# D1H register map
Vendor: Allwinner; File version: 1.0
Registers are 32-bit, read-write, reset 0x0 unless marked. A register's access mark holds for its fields unless they carry their own. Offsets are from the block's base; [hi:lo] are bit positions; {n}, {i} and the like mark numbered series.

## SPI0 — Serial Peripheral Interface
Base 0x04025000
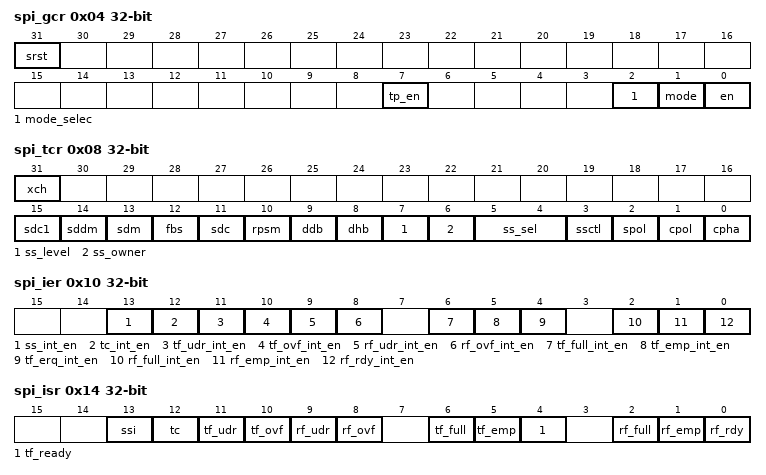
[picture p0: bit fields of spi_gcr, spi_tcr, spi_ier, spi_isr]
0x04 spi_gcr — SPI Global Control Register
  [31] srst — Soft reset
  [7] tp_en — Transmit Pause Enable
    0=NORMAL (normal operation, ignore RXFIFO status); 1=STOP_WHEN_FULL (Stop transmit data when RXFIFO full)
  [2] mode_selec — Sample timing Mode Select
    0=OLD_MODE (Old mode of Sample Timing); 1=NEW_MODE (New mode of Sample Timing)
  [1] mode — SPI Function Mode Select
    0=SLAVE; 1=MASTER
  [0] en — SPI Module Enable Control
    0=DISABLE; 1=ENABLE
0x08 spi_tcr — SPI Transfer Control Register
  [31] xch — Exchange Burst
    0=IDLE; 1=INITIATE_EXCHANGE
  [15] sdc1 — Master Sample Data Control register1
    0=NORMAL (normal operation, do not delay the internal read sample point); 1=DELAY (delay the internal read sample point)
  [14] sddm — Sending Data Delay Mode
    0=NORMAL (normal sending); 1=DELAY (delay sending)
  [13] sdm — Master Sample Data Mode
    0=DELAY (delay sample mode); 1=NORMAL (normal sample mode)
  [12] fbs — First Transmit Bit Select
    0=MSB (MSB first); 1=LSB (LSB first)
  [11] sdc — Master Sample Data Control
    0=NORMAL (Normal operation, do not delay the internal read sample point); 1=DELAY (Delay the internal read sample point)
  [10] rpsm — Rapids Mode Select
    0=NORMAL (Normal write mode); 1=RAPID (Rapid write mode)
  [9] ddb — Dummy Burst Type
    0=ZERO (The bit value of dummy SPI burst is zero); 1=ONE (The bit value of dummy SPI burst is one)
  [8] dhb — Discard Hash Burst
    0=RECEIVE (Receiving all SPI bursts in the BC period); 1=DISCARD (Discard unused SPI bursts)
  [7] ss_level
    0=LOW; 1=HIGH
  [6] ss_owner
    0=SPI_CONTROLLER; 1=SOFTWARE
  [5:4] ss_sel
    {v}=SS{v} (v=0..3)
  [3] ssctl
    0=ASSERT (SPI_SSx remains asserted between SPI bursts); 1=NEGATE (Negate SPI_SSx between SPI bursts)
  [2] spol — SPI Chip Select Signal Polarity Control
    0=HIGH (Active high polarity); 1=LOW (Active low polarity)
  [1] cpol — SPI Clock Polarity Control
    0=HIGH (Active high polarity); 1=LOW (Active low polarity)
  [0] cpha — SPI Clock/Data Phase Control
    0=P0 (Phase 0 (Leading edge for sample data)); 1=P1 (Phase 1 (Leading edge for setup data))
0x10 spi_ier — SPI Interrupt Control Register
  [all] fields
    0=DISABLE; 1=ENABLE
  [13] ss_int_en — SSI Interrupt Enable
  [12] tc_int_en — Transfer Completed Interrupt Enable
  [11] tf_udr_int_en — TXFIFO Underrun Interrupt Enable
  [10] tf_ovf_int_en — TXFIFO Overflow Interrupt Enable
  [9] rf_udr_int_en — RXFIFO Underrun Interrupt Enable
  [8] rf_ovf_int_en — RXFIFO Overflow Interrupt Enable
  [6] tf_full_int_en — TXFIFO Full Interrupt Enable
  [5] tf_emp_int_en — TXFIFO Empty Interrupt Enable
  [4] tf_erq_int_en — TXFIFO Empty Request Interrupt Enable
  [2] rf_full_int_en — RXFIFO Full Interrupt Enable
  [1] rf_emp_int_en — RXFIFO Empty Interrupt Enable
  [0] rf_rdy_int_en — RXFIFO Ready Request Interrupt Enable
0x14 spi_isr — SPI Interrupt Status Register
  [13] ssi — SS Invalid Enable
  [12] tc — Transfer Completed
    0=BUSY; 1=TRANSFER_COMPLETED
  [11] tf_udr — TXFIFO Underrun
    0=NOT_UNDERRUN; 1=UNDERRUN
  [10] tf_ovf — TXFIFO Overflow
    0=NOT_OVERFLOW; 1=OVERFLOW
  [9] rf_udr — RXFIFO Underrun
    0=NOT_UNDERRUN; 1=UNDERRUN
  [8] rf_ovf — RXFIFO Overflow
    0=NOT_OVERFLOW; 1=OVERFLOW
  [6] tf_full — TXFIFO Full
    0=NOT_FULL; 1=FULL
  [5] tf_emp — TXFIFO Empty
    0=NOT_EMPTY; 1=EMPTY
  [4] tf_ready — TXFIFO Ready
  [2] rf_full — RXFIFO Full
    0=NOT_FULL; 1=FULL
  [1] rf_emp — RXFIFO Empty
    0=NOT_EMPTY; 1=EMPTY
  [0] rf_rdy — RXFIFO Ready
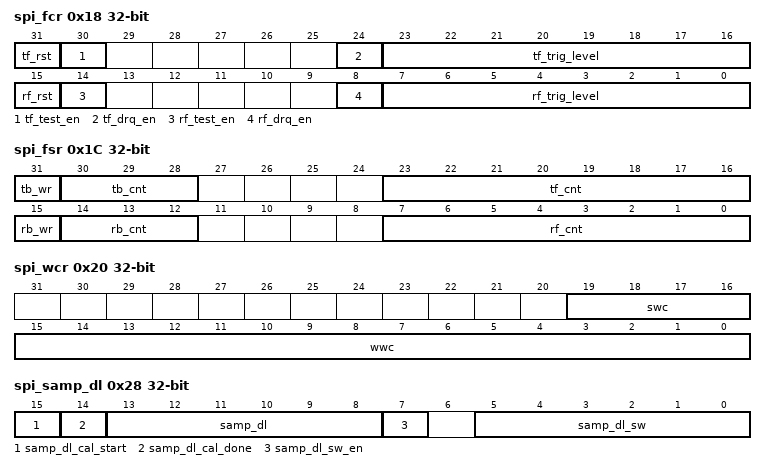
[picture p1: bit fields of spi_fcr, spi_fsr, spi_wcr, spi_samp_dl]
0x18 spi_fcr — SPI FIFO Control Register
  [31] tf_rst — TXFIFO Reset
  [30] tf_test_en — TXFIFO Test Mode Enable
    0=DISABLE; 1=ENABLE
  [24] tf_drq_en — TXFIFO DMA Request Enable
    0=DISABLE; 1=ENABLE
  [23:16] tf_trig_level — TXFIFO Empty Request Trigger Level
  [15] rf_rst — RXFIFO Reset
  [14] rf_test_en — RXFIFO Test Mode Enable
    0=DISABLE; 1=ENABLE
  [8] rf_drq_en — RXFIFO DMA Request Enable
    0=DISABLE; 1=ENABLE
  [7:0] rf_trig_level — RXFIFO Ready Request Trigger Level
0x1C spi_fsr ro — SPI FIFO Status Register
  [31] tb_wr — TXFIFO Write Buffer Write Enable
  [30:28] tb_cnt — TXFIFO Write Buffer Counter
  [23:16] tf_cnt — TXFIFO Counter . These bits indicate the number of bytes in TXFIFO
  [15] rb_wr — RXFIFO Write Buffer Write Enable
  [14:12] rb_cnt — RXFIFO Write Buffer Counter
  [7:0] rf_cnt — RXFIFO Counter . These bits indicate the number of bytes in RXFIFO
0x20 spi_wcr — SPI Wait Clock Register
  [19:16] swc — Dual mode direction switch wait clock counter
  [15:0] wwc — Wait clock counter
0x28 spi_samp_dl — SPI Sample Delay Control Register
  [15] samp_dl_cal_start — Sample Delay Calibration Start
  [14] samp_dl_cal_done ro — Sample Delay Calibration Dont
  [13:8] samp_dl ro — Sample Delay
  [7] samp_dl_sw_en — Sample Delay Software Enable
  [5:0] samp_dl_sw — Sample Delay Software
0x30 spi_mbc — SPI Master Burst Counter Register
  [23:0] mbc — Master Burst Counter
0x34 spi_mtc — SPI Master Transmit Counter Register
  [23:0] mwtc — Master Write Transmit Counter
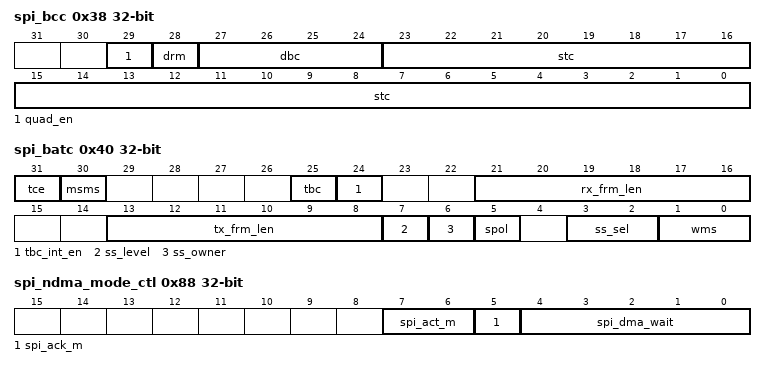
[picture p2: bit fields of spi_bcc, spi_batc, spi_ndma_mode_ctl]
0x38 spi_bcc — SPI Master Burst Control Register
  [29] quad_en — Quad Mode Enable
    0=DISABLE; 1=ENABLE
  [28] drm — Master Dual Mode RX Enable
    0=SINGLE; 1=DUAL
  [27:24] dbc — Master Dummy Burst Counter
  [23:0] stc — Master Single Mode Transmit Counter
0x40 spi_batc — SPI Bit-Aligned Transfer Configure Register
  [31] tce — Transfer Control Enable
    0=IDLE; 1=INIT
  [30] msms — Master Sample Standard
    0=DELAY; 1=STANDARD
  [25] tbc — Transfer Bits Completed
    0=BUSY; 1=COMPLETED
  [24] tbc_int_en — Transfer Bits Completed Interrupt Enable
    0=DISABLE; 1=ENABLE
  [21:16] rx_frm_len — Configure the length of serial data frame of RX
  [13:8] tx_frm_len — Configure the length of serial data frame of TX
  [7] ss_level
    0=LOW; 1=HIGH
  [6] ss_owner — SS Output Owner Select
    0=SPI_CONTROLLER; 1=SOFTWARE
  [5] spol — SPI Chip Select Signal Polarity Control
    0=HIGH; 1=LOW
  [3:2] ss_sel — SPI Chip Select
    {v}=SS{v} (v=0..3)
  [1:0] wms — Work Mode Select
    0=BYTE_ALIGNED; 2=BIT_ALIGNED_3WIRE; 3=BIT_ALIGNED_STANDARD
0x44 spi_ba_ccr — SPI Bit-Aligned Clock Configuration Register
  [7:0] cdr_n — Clock Divide Rate
0x48 spi_tbr — SPI TX Bit Register . VTB [31:0]: The Value of the Transmit Bits
0x4C spi_rbr — SPI RX Bit Register . VRB [31:0]: The Value of the Receive Bits
0x88 spi_ndma_mode_ctl — SPI Normal DMA Mode Control Register
  [7:6] spi_act_m — SPI NDMA Active Mode
    0=LOW; 1=HIGH; 2=DRQ_CONTROL; 3=CONTROLLER_CONTROL
  [5] spi_ack_m — SPI NDMA Acknowledge Mode
    0=IGNORE; 1=AFTER_DETECT
  [4:0] spi_dma_wait
0x200 spi_txd — SPI TX Data Register . TDATA [31:0]: Transmit Data in word method
0x200 spi_txd_16 16-bit — SPI TX Data Register . TDATA [15:0]: Transmit Data in half-word method
0x200 spi_txd_8 8-bit — SPI TX Data Register . TDATA [7:0]: Transmit Data in byte method
0x300 spi_rxd — SPI RX Data Register . RDATA [31:0]: Receive Data and access in word method
0x300 spi_rxd_16 16-bit — SPI RX Data Register . RDATA [15:0]: Receive Data and access in half-word method
0x300 spi_rxd_8 8-bit — SPI RX Data Register . RDATA [7:0]: Receive Data and access in byte method

## SPI_DBI — Serial Peripheral Interface Display Bus Interface
Base 0x04026000
Registers as SPI0, without spi_txd_16, spi_txd_8, spi_rxd_16, spi_rxd_8; these are added or differ:
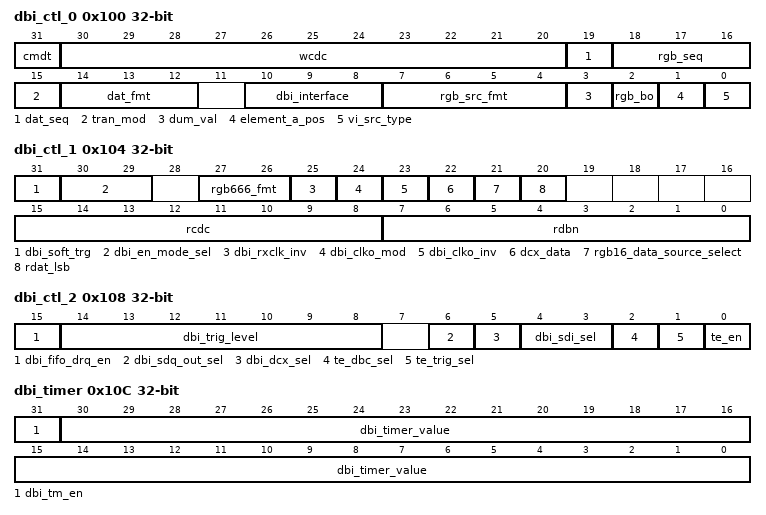
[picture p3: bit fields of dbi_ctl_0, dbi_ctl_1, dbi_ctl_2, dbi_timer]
0x100 dbi_ctl_0 — DBI Control Register 0
  [31] cmdt — Command Type
    0=WRITE; 1=READ
  [30:20] wcdc — Write Command Dummy Cycles
  [19] dat_seq — Output Data Sequence
    0=MSB; 1=LSB
  [18:16] rgb_seq — Output RGB Sequence
    0=RGB; 1=RBG; 2=GRB; 3=GBR; 4=BRG; 5=BGR
  [15] tran_mod — Transmit Mode
    0=COMMAND_PARAMETER; 1=VIDEO
  [14:12] dat_fmt — Output Data Format
    0=RGB111; 1=RGB444; 2=RGB565; 3=RGB666; 4=RGB888
  [10:8] dbi_interface
    0=L3I1 (3 Line Interface I); 1=L3I2 (3 Line Interface II); 2=L4I1 (4 Line Interface I); 3=L4I2 (4 Line Interface II); 4=D2LI (2 Data Lane Interface)
  [7:4] rgb_src_fmt — RGB Source Format
    0=RGB; 1=RBG; 2=GRB; 3=GBR; 4=BRG; 5=BGR; 6=GRBG_0; 7=GBRG_0; 8=GRBG_1; 9=GBRG_1
  [3] dum_val — Dummy Cycle Value
  [2] rgb_bo — RGB Bit Order
    0=DATA; 1=SWAP
  [1] element_a_pos — Element A Position
    0=31_24; 1=7_0
  [0] vi_src_type — Video Source Type
    0=RGB32; 1=RGB16
0x104 dbi_ctl_1 — DBI Control Register 1
  [31] dbi_soft_trg — DBI Soft Trigger
  [30:29] dbi_en_mode_sel — DBI Enable Mode Select
    0=DBI; 1=SOFTWARE; 2=TIMER; 3=TE
  [27:26] rgb666_fmt — 2 Data Lane RGB666 Format
    0=NORMAL; 1=SPECIAL_ILITEK; 2=SPECIAL_NEW_VISION
  [25] dbi_rxclk_inv — DBI RX Clock Inverse
    0=POSITIVE; 1=NEGATIVE
  [24] dbi_clko_mod — DBI Output Clock Mode
    0=ALWAYS_ON; 1=AUTO_GATING
  [23] dbi_clko_inv — DBI Clock Output Inverse
  [22] dcx_data — DCX Data Value
  [21] rgb16_data_source_select
  [20] rdat_lsb — Bit Order of Read Data
  [15:8] rcdc — Read Command Dummy Cycles
  [7:0] rdbn — Read Data Number of Bytes
0x108 dbi_ctl_2 — DBI Control Register 2
  [15] dbi_fifo_drq_en — DBI FIFO DMA Request Enable
  [14:8] dbi_trig_level — DBI FIFO Empty Request Trigger Level
  [6] dbi_sdq_out_sel — DBI SDI PIN Output Select
  [5] dbi_dcx_sel — DBI DCX PIN Function Select
  [4:3] dbi_sdi_sel — DBI SDI PIN FUnction Select
    0=DBI_SDI; 1=DBI_TE; 2=DBI_DCX
  [2] te_dbc_sel — TE debounce function select
  [1] te_trig_sel — TE edge trigger select
  [0] te_en — TE Enable
0x10C dbi_timer — DBI Timer Control Register
  [31] dbi_tm_en — DBI Timer Enable
    0=ENABLE; 1=DISABLE
  [30:0] dbi_timer_value
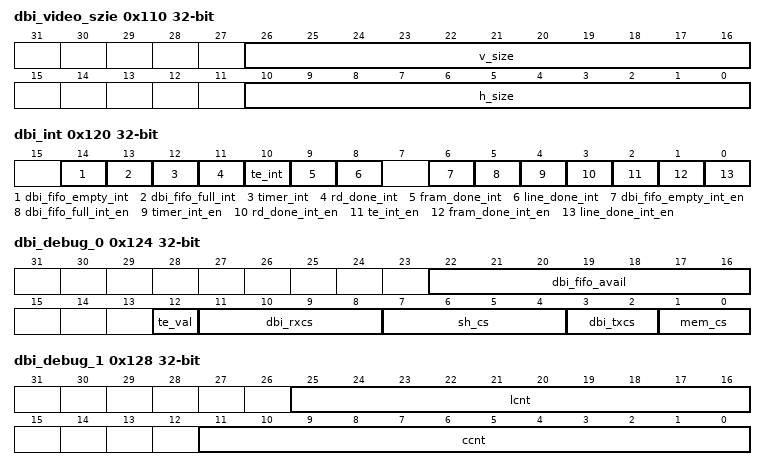
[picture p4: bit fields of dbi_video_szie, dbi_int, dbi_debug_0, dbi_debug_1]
0x110 dbi_video_szie — DBI Video Size Configuration Register
  [26:16] v_size, [10:0] h_size
0x120 dbi_int — DBI Interrupt Register
  [14] dbi_fifo_empty_int, [13] dbi_fifo_full_int, [12] timer_int, [11] rd_done_int, [10] te_int, [9] fram_done_int, [8] line_done_int, [6] dbi_fifo_empty_int_en, [5] dbi_fifo_full_int_en, [4] timer_int_en, [3] rd_done_int_en, [2] te_int_en, [1] fram_done_int_en, [0] line_done_int_en
0x124 dbi_debug_0 ro — DBI BEBUG 0 Register
  [22:16] dbi_fifo_avail, [12] te_val, [11:8] dbi_rxcs, [7:4] sh_cs, [3:2] dbi_txcs, [1:0] mem_cs
0x128 dbi_debug_1 ro — DBI BEBUG 1 Register
  [25:16] lcnt, [11:0] ccnt
0x200 spi_txd — SPI TX Data Register . TDATA [31:0]: Transmit Data
0x300 spi_rxd — SPI RX Data Register . RDATA [31:0]: Receive Data
